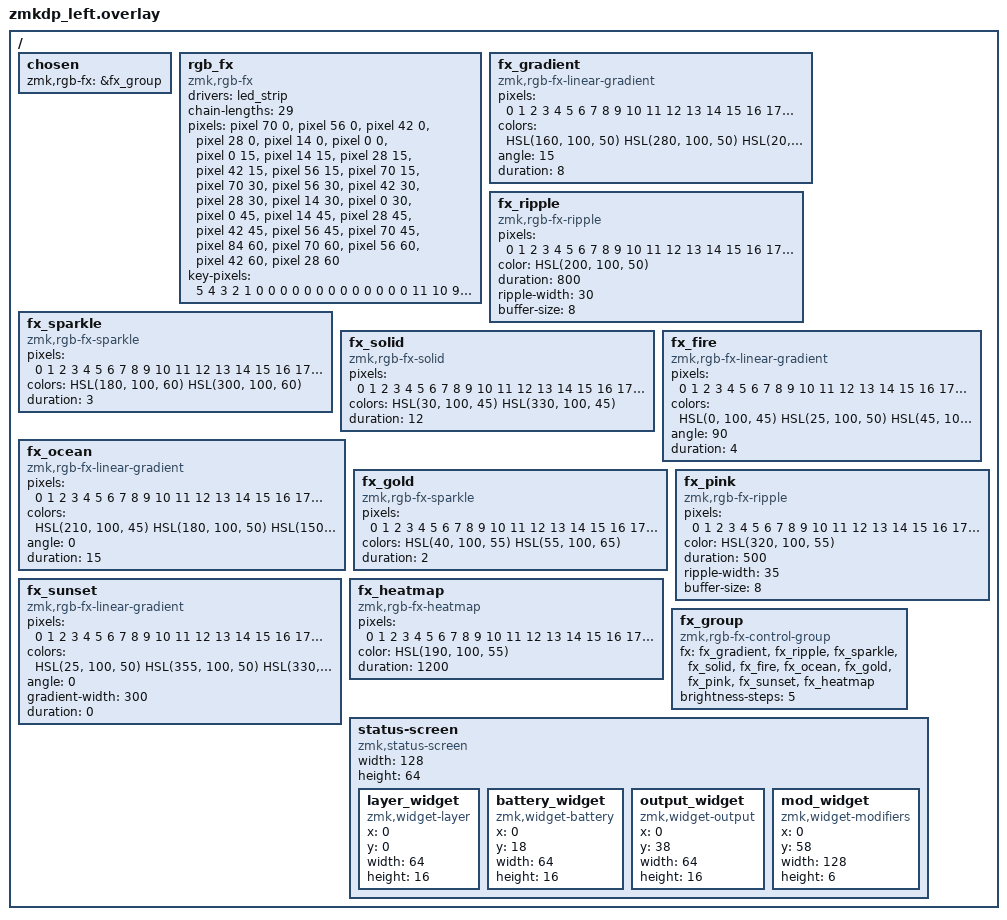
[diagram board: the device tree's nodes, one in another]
/*
 * RGB FX - left half (zmkdp, 29 LEDs).
 *
 * Axis-mirror of the right half (config/zmkdp_right.overlay), whose
 * chain was confirmed by an annotated PCB photo (2026-10): the chain
 * starts at the top-INNER LED next to the MCU and snakes across the
 * board, alternating direction every row; the standalone corner light
 * at the inner bottom is pixel 24, mid-chain, NOT the chain start.
 * Mirrored to the left half (x = 300 - x_right) this yields:
 *
 *     (keyboard view, outer edge on the LEFT, seam on the RIGHT)
 *         5  4  3  2  1  0
 *        11 10  9  8  7  6
 *        17 16 15 14 13 12
 *        18 19 20 21 22 23
 *        28 27 26 25 24      <- 24 = inner-bottom corner light
 *
 * Rows 1-4 have LEDs under all 6 columns; the bottom row only under
 * the inner 4 columns plus the corner light. Canvas: x 0 (outer) ..
 * 84 (inner), y 0 (top) .. 60 (bottom). Column step 14, row step 15.
 *
 * NOTE: ONLY the left half uses this numbering. The right half keeps
 * its own mapping (config/zmkdp_right.overlay) and was NOT changed.
 *
 * key-pixels: 18 entries per row (7 left + 7 right + 4 third), matching
 * the matrix transform in zmkdp.dtsi. Remote keys (right/third) alias
 * to pixel 0 (inner top) so ripples enter from the seam. The inner 7th
 * column has no LED in rows 1-4 and aliases to its row's inner LED.
 */

#include <rgb_fx.dtsi>
#include <dt-bindings/zmk/rgb_fx.h>

/ {
    chosen {
        zmk,rgb-fx = &fx_group;
    };

    rgb_fx: rgb_fx {
        compatible = "zmk,rgb-fx";
        drivers = <&led_strip>;
        chain-lengths = <29>;
        pixels
            = <&pixel 70 0>,   /*  0 = top row, inner seam (chain start, MCU side) */
              <&pixel 56 0>,   /*  1 */
              <&pixel 42 0>,   /*  2 */
              <&pixel 28 0>,   /*  3 */
              <&pixel 14 0>,   /*  4 */
              <&pixel 0 0>,    /*  5 = top row, outer */
              <&pixel 0 15>,   /*  6 = row 2, outer */
              <&pixel 14 15>,  /*  7 */
              <&pixel 28 15>,  /*  8 */
              <&pixel 42 15>,  /*  9 */
              <&pixel 56 15>,  /* 10 */
              <&pixel 70 15>,  /* 11 = row 2, inner seam */
              <&pixel 70 30>,  /* 12 = row 3, inner seam */
              <&pixel 56 30>,  /* 13 */
              <&pixel 42 30>,  /* 14 */
              <&pixel 28 30>,  /* 15 */
              <&pixel 14 30>,  /* 16 */
              <&pixel 0 30>,   /* 17 = row 3, outer */
              <&pixel 0 45>,   /* 18 = row 4, outer */
              <&pixel 14 45>,  /* 19 */
              <&pixel 28 45>,  /* 20 */
              <&pixel 42 45>,  /* 21 */
              <&pixel 56 45>,  /* 22 */
              <&pixel 70 45>,  /* 23 = row 4, inner seam */
              <&pixel 84 60>,  /* 24 = inner-bottom corner light */
              <&pixel 70 60>,  /* 25 = bottom row, inner */
              <&pixel 56 60>,  /* 26 */
              <&pixel 42 60>,  /* 27 */
              <&pixel 28 60>;  /* 28 = bottom row, outer */
        key-pixels
            = < 5  4  3  2  1  0  0   0 0 0 0 0 0 0   0 0 0 0
               11 10  9  8  7  6  6   0 0 0 0 0 0 0   0 0 0 0
               17 16 15 14 13 12 12   0 0 0 0 0 0 0   0 0 0 0
               18 19 20 21 22 23 23   0 0 0 0 0 0 0   0 0 0 0
               18 28 28 27 26 25 24   0 0 0 0 0 0 0   0 0 0 0>;
    };

    fx_gradient: fx_gradient {
        compatible = "zmk,rgb-fx-linear-gradient";
        pixels = <0 1 2 3 4 5 6 7 8 9 10 11 12 13 14 15 16 17 18 19 20 21 22 23 24 25 26 27 28>;
        colors = <HSL(160, 100, 50) HSL(280, 100, 50) HSL(20, 100, 50)>;
        angle = <15>;
        duration = <8>;
    };

    fx_ripple: fx_ripple {
        compatible = "zmk,rgb-fx-ripple";
        pixels = <0 1 2 3 4 5 6 7 8 9 10 11 12 13 14 15 16 17 18 19 20 21 22 23 24 25 26 27 28>;
        color = <HSL(200, 100, 50)>;
        duration = <800>;
        ripple-width = <30>;
        buffer-size = <8>;
    };

    fx_sparkle: fx_sparkle {
        compatible = "zmk,rgb-fx-sparkle";
        pixels = <0 1 2 3 4 5 6 7 8 9 10 11 12 13 14 15 16 17 18 19 20 21 22 23 24 25 26 27 28>;
        colors = <HSL(180, 100, 60) HSL(300, 100, 60)>;
        duration = <3>;
    };

    fx_solid: fx_solid {
        compatible = "zmk,rgb-fx-solid";
        pixels = <0 1 2 3 4 5 6 7 8 9 10 11 12 13 14 15 16 17 18 19 20 21 22 23 24 25 26 27 28>;
        colors = <HSL(30, 100, 45) HSL(330, 100, 45)>;
        duration = <12>;
    };

    fx_fire: fx_fire {
        compatible = "zmk,rgb-fx-linear-gradient";
        pixels = <0 1 2 3 4 5 6 7 8 9 10 11 12 13 14 15 16 17 18 19 20 21 22 23 24 25 26 27 28>;
        colors = <HSL(0, 100, 45) HSL(25, 100, 50) HSL(45, 100, 55)>;
        angle = <90>;
        duration = <4>;
    };

    fx_ocean: fx_ocean {
        compatible = "zmk,rgb-fx-linear-gradient";
        pixels = <0 1 2 3 4 5 6 7 8 9 10 11 12 13 14 15 16 17 18 19 20 21 22 23 24 25 26 27 28>;
        colors = <HSL(210, 100, 45) HSL(180, 100, 50) HSL(150, 90, 45)>;
        angle = <0>;
        duration = <15>;
    };

    fx_gold: fx_gold {
        compatible = "zmk,rgb-fx-sparkle";
        pixels = <0 1 2 3 4 5 6 7 8 9 10 11 12 13 14 15 16 17 18 19 20 21 22 23 24 25 26 27 28>;
        colors = <HSL(40, 100, 55) HSL(55, 100, 65)>;
        duration = <2>;
    };

    fx_pink: fx_pink {
        compatible = "zmk,rgb-fx-ripple";
        pixels = <0 1 2 3 4 5 6 7 8 9 10 11 12 13 14 15 16 17 18 19 20 21 22 23 24 25 26 27 28>;
        color = <HSL(320, 100, 55)>;
        duration = <500>;
        ripple-width = <35>;
        buffer-size = <8>;
    };

    fx_sunset: fx_sunset {
        compatible = "zmk,rgb-fx-linear-gradient";
        pixels = <0 1 2 3 4 5 6 7 8 9 10 11 12 13 14 15 16 17 18 19 20 21 22 23 24 25 26 27 28>;
        colors = <HSL(25, 100, 50) HSL(355, 100, 50) HSL(330, 100, 50)
                  HSL(285, 100, 50) HSL(235, 100, 50)>;
        angle = <0>;
        gradient-width = <300>;
        duration = <0>;
    };

    fx_heatmap: fx_heatmap {
        compatible = "zmk,rgb-fx-heatmap";
        pixels = <0 1 2 3 4 5 6 7 8 9 10 11 12 13 14 15 16 17 18 19 20 21 22 23 24 25 26 27 28>;
        color = <HSL(190, 100, 55)>;
        duration = <1200>;
    };

    fx_group: fx_group {
        compatible = "zmk,rgb-fx-control-group";
        fx = <&fx_gradient &fx_ripple &fx_sparkle &fx_solid
              &fx_fire &fx_ocean &fx_gold &fx_pink &fx_sunset &fx_heatmap>;
        brightness-steps = <5>;
    };
};




/ {
    status-screen {
        compatible = "zmk,status-screen";
        width = <128>;
        height = <64>;
        #address-cells = <1>;
        #size-cells = <1>;

        layer_widget {
            compatible = "zmk,widget-layer";
            x = <0>;
            y = <0>;
            width = <64>;
            height = <16>;
        };

        battery_widget {
            compatible = "zmk,widget-battery";
            x = <0>;
            y = <18>;
            width = <64>;
            height = <16>;
        };

        output_widget {
            compatible = "zmk,widget-output";
            x = <0>;
            y = <38>;
            width = <64>;
            height = <16>;
        };

        mod_widget {
            compatible = "zmk,widget-modifiers";
            x = <0>;
            y = <58>;
            width = <128>;
            height = <6>;
        };
    };
};
